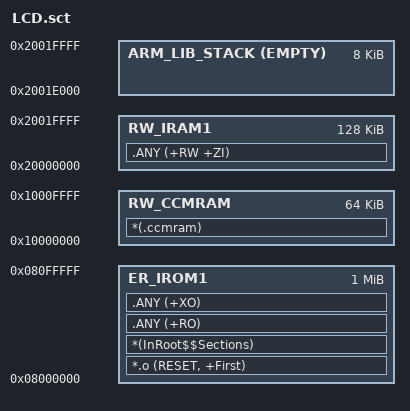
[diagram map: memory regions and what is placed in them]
; *************************************************************
; *** Scatter-Loading Description File generated by uVision ***
; *************************************************************

LR_IROM1 0x08000000 0x00100000  {    ; load region size_region
  ER_IROM1 0x08000000 0x00100000  {  ; load address = execution address
   *.o (RESET, +First)
   *(InRoot$$Sections)
   .ANY (+RO)
   .ANY (+XO)
  }
  ; RW_IRAM1 0x20000000 0x0001C000  {  ; RW data
  ; .ANY (+RW +ZI)
  ;}
  ;RW_IRAM2 0x2001C000 0x00004000  {
  ; .ANY (+RW +ZI)
  ;}
   RW_IRAM1 0x20000000 0x00020000  {  ; 128KB 连续空间
   .ANY (+RW +ZI)
  }
  
    ; 强制把栈顶推到 128KB 的尽头
  ; 0x20020000 是 128KB 结束地址，-0x2000 是8KB 栈大小
    ARM_LIB_STACK 0x20020000 EMPTY -0x2000 {
  }

  RW_CCMRAM 0x10000000 0x00010000  {
   *(.ccmram)
  }
}

